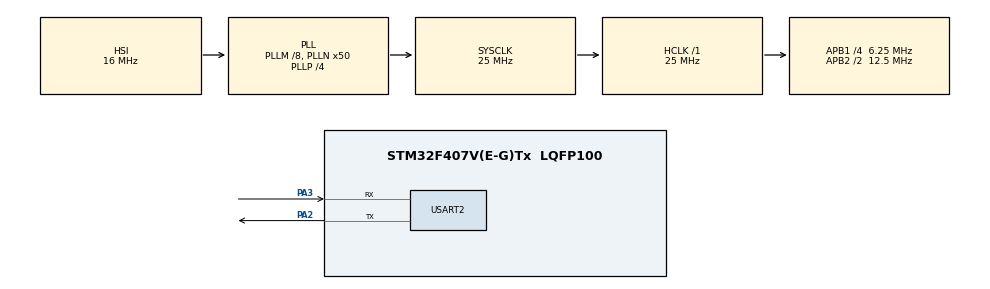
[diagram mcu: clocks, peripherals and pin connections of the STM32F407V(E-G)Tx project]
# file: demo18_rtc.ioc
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Mcu.Family=STM32F4
RCC.CortexFreq_Value=25000000
VP_RTC_VS_RTC_Activate.Mode=RTC_Enabled
RCC.APB1CLKDivider=RCC_HCLK_DIV4
RCC.SYSCLKSource=RCC_SYSCLKSOURCE_PLLCLK
ProjectManager.StackSize=0x400
PA3.Mode=Asynchronous
ProjectManager.TargetToolchain=STM32CubeIDE
RTC.Year=22
RCC.HCLKFreq_Value=25000000
RCC.APB2TimFreq_Value=25000000
RTC.Format=RTC_FORMAT_BIN
RCC.LSE_VALUE=32768
RCC.AHBFreq_Value=25000000
RCC.HSE_VALUE=8000000
RTC.Minutes=40
board=STM32F407G-DISC1
RCC.VCOOutputFreq_Value=100000000
RCC.APB2Freq_Value=12500000
RTC.Month=RTC_MONTH_MAY
Mcu.Name=STM32F407V(E-G)Tx
PA2.Signal=USART2_TX
RCC.48MHZClocksFreq_Value=14285714.285714285
RCC.SYSCLKFreq_VALUE=25000000
RTC.Hours=3
Mcu.Package=LQFP100
USART2.VirtualMode=VM_ASYNC
VP_RTC_VS_RTC_Calendar.Mode=RTC_Calendar
RTC.HourFormat=RTC_HOURFORMAT_12
ProjectManager.HeapSize=0x200
RCC.HSI_VALUE=16000000
RCC.PLLP=RCC_PLLP_DIV4
RCC.PLLQ=7
NVIC.PriorityGroup=NVIC_PRIORITYGROUP_0
RCC.APB2CLKDivider=RCC_HCLK_DIV2
RCC.PLLM=8
RCC.PLLN=50
RCC.APB1TimFreq_Value=12500000
PA2.Mode=Asynchronous
RCC.APB1Freq_Value=6250000
RTC.Date=30
PA3.Signal=USART2_RX

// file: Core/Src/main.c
/* USER CODE BEGIN Header */
/**
  ******************************************************************************
  * @file           : main.c
  * @brief          : Main program body
  ******************************************************************************
  * @attention
  *
  * <h2><center>&copy; Copyright (c) 2022 STMicroelectronics.
  * All rights reserved.</center></h2>
  *
  * This software component is licensed by ST under BSD 3-Clause license,
  * the "License"; You may not use this file except in compliance with the
  * License. You may obtain a copy of the License at:
  *                        opensource.org/licenses/BSD-3-Clause
  *
  ******************************************************************************
  */
/* USER CODE END Header */
#include "main.h"

/* USER CODE BEGIN Includes */
#include<stdio.h>
/* USER CODE END Includes */

RTC_HandleTypeDef hrtc;

UART_HandleTypeDef huart2;

void SystemClock_Config(void);
static void MX_GPIO_Init(void);
static void MX_RTC_Init(void);
static void MX_USART2_UART_Init(void);

int main(void)
{
  /* USER CODE BEGIN 1 */
 RTC_DateTypeDef date;
 RTC_TimeTypeDef time;
 char str[50];
 int len;
  /* USER CODE END 1 */

  /* MCU Configuration--------------------------------------------------------*/

  /* Reset of all peripherals, Initializes the Flash interface and the Systick. */
  HAL_Init();

  /* Configure the system clock */
  SystemClock_Config();

  /* Initialize all configured peripherals */
  MX_GPIO_Init();
  MX_RTC_Init();
  MX_USART2_UART_Init();

  /* Infinite loop */
  while (1)
  {
	  HAL_RTC_GetDate(&hrtc, &date, RTC_FORMAT_BIN);
	  HAL_RTC_GetTime(&hrtc, &time, RTC_FORMAT_BIN);

	  len = sprintf(str, "%02d-%02d-%02d  %02d:%02d:%02d\r\n",(int)date.Date,(int)date.Month,(int)date.Year,(int)time.Hours,(int)time.Minutes,(int)time.Seconds);

	  HAL_UART_Transmit(&huart2, (uint8_t*)str, len, HAL_MAX_DELAY);

	  HAL_Delay(1000);

  }
}

void SystemClock_Config(void)
{
  RCC_OscInitTypeDef RCC_OscInitStruct = {0};
  RCC_ClkInitTypeDef RCC_ClkInitStruct = {0};
  RCC_PeriphCLKInitTypeDef PeriphClkInitStruct = {0};

  /** Configure the main internal regulator output voltage
  */
  __HAL_RCC_PWR_CLK_ENABLE();
  __HAL_PWR_VOLTAGESCALING_CONFIG(PWR_REGULATOR_VOLTAGE_SCALE1);
  /** Initializes the RCC Oscillators according to the specified parameters
  * in the RCC_OscInitTypeDef structure.
  */
  RCC_OscInitStruct.OscillatorType = RCC_OSCILLATORTYPE_HSI|RCC_OSCILLATORTYPE_LSI;
  RCC_OscInitStruct.HSIState = RCC_HSI_ON;
  RCC_OscInitStruct.HSICalibrationValue = RCC_HSICALIBRATION_DEFAULT;
  RCC_OscInitStruct.LSIState = RCC_LSI_ON;
  RCC_OscInitStruct.PLL.PLLState = RCC_PLL_ON;
  RCC_OscInitStruct.PLL.PLLSource = RCC_PLLSOURCE_HSI;
  RCC_OscInitStruct.PLL.PLLM = 8;
  RCC_OscInitStruct.PLL.PLLN = 50;
  RCC_OscInitStruct.PLL.PLLP = RCC_PLLP_DIV4;
  RCC_OscInitStruct.PLL.PLLQ = 7;
  if (HAL_RCC_OscConfig(&RCC_OscInitStruct) != HAL_OK)
  {
    Error_Handler();
  }
  /** Initializes the CPU, AHB and APB buses clocks
  */
  RCC_ClkInitStruct.ClockType = RCC_CLOCKTYPE_HCLK|RCC_CLOCKTYPE_SYSCLK
                              |RCC_CLOCKTYPE_PCLK1|RCC_CLOCKTYPE_PCLK2;
  RCC_ClkInitStruct.SYSCLKSource = RCC_SYSCLKSOURCE_PLLCLK;
  RCC_ClkInitStruct.AHBCLKDivider = RCC_SYSCLK_DIV1;
  RCC_ClkInitStruct.APB1CLKDivider = RCC_HCLK_DIV4;
  RCC_ClkInitStruct.APB2CLKDivider = RCC_HCLK_DIV2;

  if (HAL_RCC_ClockConfig(&RCC_ClkInitStruct, FLASH_LATENCY_0) != HAL_OK)
  {
    Error_Handler();
  }
  PeriphClkInitStruct.PeriphClockSelection = RCC_PERIPHCLK_RTC;
  PeriphClkInitStruct.RTCClockSelection = RCC_RTCCLKSOURCE_LSI;
  if (HAL_RCCEx_PeriphCLKConfig(&PeriphClkInitStruct) != HAL_OK)
  {
    Error_Handler();
  }
}

static void MX_RTC_Init(void)
{

  RTC_TimeTypeDef sTime = {0};
  RTC_DateTypeDef sDate = {0};

  /** Initialize RTC Only
  */
  hrtc.Instance = RTC;
  hrtc.Init.HourFormat = RTC_HOURFORMAT_12;
  hrtc.Init.AsynchPrediv = 127;
  hrtc.Init.SynchPrediv = 255;
  hrtc.Init.OutPut = RTC_OUTPUT_DISABLE;
  hrtc.Init.OutPutPolarity = RTC_OUTPUT_POLARITY_HIGH;
  hrtc.Init.OutPutType = RTC_OUTPUT_TYPE_OPENDRAIN;
  if (HAL_RTC_Init(&hrtc) != HAL_OK)
  {
    Error_Handler();
  }

  /** Initialize RTC and set the Time and Date
  */
  sTime.Hours = 3;
  sTime.Minutes = 40;
  sTime.Seconds = 0;
  sTime.TimeFormat = RTC_HOURFORMAT12_AM;
  sTime.DayLightSaving = RTC_DAYLIGHTSAVING_NONE;
  sTime.StoreOperation = RTC_STOREOPERATION_RESET;
  if (HAL_RTC_SetTime(&hrtc, &sTime, RTC_FORMAT_BIN) != HAL_OK)
  {
    Error_Handler();
  }
  sDate.WeekDay = RTC_WEEKDAY_MONDAY;
  sDate.Month = RTC_MONTH_MAY;
  sDate.Date = 30;
  sDate.Year = 0;

  if (HAL_RTC_SetDate(&hrtc, &sDate, RTC_FORMAT_BIN) != HAL_OK)
  {
    Error_Handler();
  }

}

static void MX_USART2_UART_Init(void)
{

  huart2.Instance = USART2;
  huart2.Init.BaudRate = 115200;
  huart2.Init.WordLength = UART_WORDLENGTH_8B;
  huart2.Init.StopBits = UART_STOPBITS_1;
  huart2.Init.Parity = UART_PARITY_NONE;
  huart2.Init.Mode = UART_MODE_TX_RX;
  huart2.Init.HwFlowCtl = UART_HWCONTROL_NONE;
  huart2.Init.OverSampling = UART_OVERSAMPLING_16;
  if (HAL_UART_Init(&huart2) != HAL_OK)
  {
    Error_Handler();
  }

}

static void MX_GPIO_Init(void)
{

  /* GPIO Ports Clock Enable */
  __HAL_RCC_GPIOA_CLK_ENABLE();

}

void Error_Handler(void)
{
  __disable_irq();
  while (1)
  {
  }
}

/************************ (C) COPYRIGHT STMicroelectronics *****END OF FILE****/
